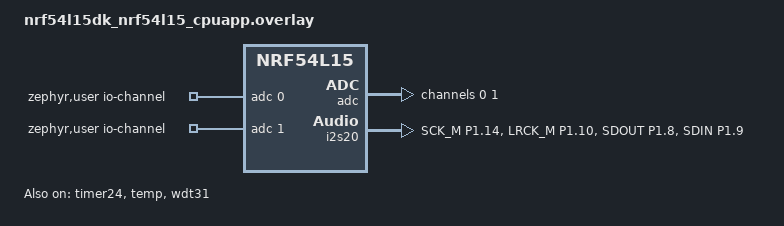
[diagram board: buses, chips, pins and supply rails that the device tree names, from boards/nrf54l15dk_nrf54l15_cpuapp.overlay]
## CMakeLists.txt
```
#
# Copyright (c) 2024 Nordic Semiconductor ASA
#
# SPDX-License-Identifier: LicenseRef-Nordic-5-Clause
#

cmake_minimum_required(VERSION 3.20.0)
find_package(Zephyr REQUIRED HINTS $ENV{ZEPHYR_BASE})
project(periph_stress)

FILE(GLOB app_sources src/*.c)

zephyr_include_directories_ifdef(CONFIG_DT_HAS_SNPS_DWC2_ENABLED ${ZEPHYR_BASE}/samples/subsys/usb/common)
zephyr_sources_ifdef(CONFIG_DT_HAS_SNPS_DWC2_ENABLED ${ZEPHYR_BASE}/samples/subsys/usb/common/sample_usbd_init.c)

target_sources(app PRIVATE ${app_sources})
```

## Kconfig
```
source "${ZEPHYR_BASE}/samples/subsys/usb/common/Kconfig.sample_usbd"

source "Kconfig.zephyr"
```

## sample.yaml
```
sample:
  name: Peripheral stress test

common:
  depends_on:
    - adc
    - gpio
    - i2c
    - pwm
    - spi
    - watchdog
  tags:
    - drivers
    - spi
    - sensors
    - ci_tests_benchmarks_peripheral_load
  harness: console

tests:
  sample.benchmarks.peripheral_stress_test.nrf54h:
    filter: not CONFIG_COVERAGE
    harness_config:
      fixture: pca63566
      type: multi_line
      ordered: false
      regex:
        - ".*Accelerometer thread has completed"
        - ".*ADC thread has completed"
        - ".*BME680 thread has completed"
        - ".*CAN thread has completed"
        - ".*Counter thread has completed"
        - ".*Flash thread has completed"
        - ".*GPIO thread has completed"
        - ".*PWM thread has completed"
        - ".*TEMP thread has completed"
        - ".*Timer thread has completed"
        - ".*WDT thread has completed"
        - ".*CPU load thread has completed"
        - ".*Clock thread has completed"
        - ".*usb_thread: Baudrate 9600"
        - ".*Bluetooth init OK"
        - ".*all \\d{1,} threads have completed"
    extra_args:
      - SHIELD=pca63566
      - SB_CONFIG_NETCORE_IPC_RADIO=y
      - SB_CONFIG_NETCORE_IPC_RADIO_BT_HCI_IPC=y
    platform_allow: nrf54h20dk/nrf54h20/cpuapp
    integration_platforms:
      - nrf54h20dk/nrf54h20/cpuapp

  sample.benchmarks.peripheral_stress_test.nrf54l:
    filter: not CONFIG_COVERAGE
    harness_config:
      fixture: pca63565
      type: multi_line
      ordered: false
      regex:
        - ".*Accelerometer thread has completed"
        - ".*ADC thread has completed"
        - ".*BME680 thread has completed"
        - ".*Counter thread has completed"
        - ".*Flash thread has completed"
        - ".*GPIO thread has completed"
        - ".*I2S thread has completed"
        - ".*PWM thread has completed"
        - ".*TEMP thread has completed"
        - ".*Timer thread has completed"
        - ".*WDT thread has completed"
        - ".*CPU load thread has completed"
        - ".*Bluetooth init OK"
        - ".*all \\d{1,} threads have completed"
    extra_args:
      - SHIELD=pca63565
    platform_allow: nrf54l15dk/nrf54l15/cpuapp
    integration_platforms:
      - nrf54l15dk/nrf54l15/cpuapp
```

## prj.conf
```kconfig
CONFIG_LOG=y

CONFIG_SENSOR=y
CONFIG_ADC=y
CONFIG_CAN=y
CONFIG_COUNTER=y
CONFIG_FLASH=y
CONFIG_GPIO=y
CONFIG_I2S=y
CONFIG_PWM=y
CONFIG_WATCHDOG=y
CONFIG_BT=y
CONFIG_BT_DEVICE_NAME="Test beacon"
CONFIG_BT_CTLR_TX_PWR_PLUS_8=y
CONFIG_ASSERT=y
```

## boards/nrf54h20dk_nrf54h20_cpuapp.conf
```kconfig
CONFIG_CLOCK_CONTROL=y

CONFIG_USB_DEVICE_STACK_NEXT=y

CONFIG_STDOUT_CONSOLE=y
CONFIG_SERIAL=y
CONFIG_UART_LINE_CTRL=y
CONFIG_USBD_CDC_ACM_CLASS=y

CONFIG_USBD_LOG_LEVEL_WRN=y
CONFIG_UDC_DRIVER_LOG_LEVEL_WRN=y
CONFIG_USBD_CDC_ACM_LOG_LEVEL_ERR=y

CONFIG_SAMPLE_USBD_PID=0x0001
CONFIG_SAMPLE_USBD_PRODUCT="USBD CDC ACM sample"

CONFIG_SOC_NRF54H20_CPURAD_ENABLE=y
```

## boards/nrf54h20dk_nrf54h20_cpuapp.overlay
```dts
/*
 * Copyright (c) 2024 Nordic Semiconductor ASA
 *
 * SPDX-License-Identifier: LicenseRef-Nordic-5-Clause
 */

/ {
	aliases {
		test-counter = &timer137;
		watchdog0 = &wdt010;
	};

	zephyr,user {
		io-channels = <&adc 0>, <&adc 1>;
	};
};

&adc {
	#address-cells = <1>;
	#size-cells = <0>;

	channel@0 {
		reg = <0>;
		zephyr,gain = "ADC_GAIN_1_2";
		zephyr,reference = "ADC_REF_INTERNAL";
		zephyr,acquisition-time = <ADC_ACQ_TIME(ADC_ACQ_TIME_MICROSECONDS, 10)>;
		zephyr,input-positive = <NRF_SAADC_AIN4>;
		zephyr,resolution = <10>;
	};

	channel@1 {
		reg = <1>;
		zephyr,gain = "ADC_GAIN_2";
		zephyr,reference = "ADC_REF_EXTERNAL0";
		zephyr,acquisition-time = <ADC_ACQ_TIME(ADC_ACQ_TIME_MICROSECONDS, 10)>;
		zephyr,input-positive = <NRF_SAADC_AIN5>;
		zephyr,resolution = <10>;
	};
};

&mx25uw63 {
	status = "okay";
};

&timer137 {
	status = "okay";
	prescaler = <4>;
};

temp_sensor: &temp_nrfs {
	status = "okay";
};

&wdt010 {
	status = "okay";
};

&zephyr_udc0 {
	cdc_acm_uart0 {
		compatible = "zephyr,cdc-acm-uart";
	};
};
```

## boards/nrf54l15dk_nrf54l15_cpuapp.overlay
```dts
/*
 * Copyright (c) 2024 Nordic Semiconductor ASA
 *
 * SPDX-License-Identifier: LicenseRef-Nordic-5-Clause
 */

/* Rev. 0.8.1:
 * P0.00 - TX_0
 * P0.01 - RX_0
 * P0.02 - RTS_0
 * P0.03 - CTS_0
 * P0.04 - Button_3
 *
 * P1.00 - 32k_XTAL1
 * P1.01 - 32k_XTAL2
 * P1.02 - NFC_1
 * P1.03 - NFC_2
 * P1.04 - TX_1
 * P1.05 - RX_1
 * P1.06 - RTS_1
 * P1.07 - CTS_1
 * P1.08 - Button_1 / I2S_SDOUT
 * P1.09 - Button_2 / I2S_SDIN
 * P1.10 - LED_1 / I2S_LRCK_M
 * P1.11 - TWIM_SCL to BME680 + ADC_ch0
 * P1.12 - TWIM_SDA to BME680 + ADC_ch1
 * P1.13 - Button_4 / CS_BME680
 * P1.14 - LED_3 / IRQ / I2S_SCK_M
 *
 * P2.00 - QSPI
 * P2.01 - QSPI
 * P2.02 - QSPI
 * P2.03 - QSPI
 * P2.04 - QSPI
 * P2.05 - QSPI
 * P2.06 - SPIM_SCK
 * P2.07 - LED_2
 * P2.08 - SPIM_MOSI to ADXL362
 * P2.09 - LED_0 / SPIM_MISO to ADXL362
 * P2.10 - CS_ADXL362
 */

/ {
	aliases {
		i2s-node0 = &i2s20;
		test-counter = &timer24;
	};

	zephyr,user {
		io-channels = <&adc 0>, <&adc 1>;
	};
};

&pinctrl {
	i2s20_default_alt: i2s20_default_alt {
		group1 {
			psels = <NRF_PSEL(I2S_SCK_M, 1, 14)>,
				<NRF_PSEL(I2S_LRCK_M, 1, 10)>,
				<NRF_PSEL(I2S_SDOUT, 1, 8)>,
				<NRF_PSEL(I2S_SDIN, 1, 9)>;
		};
	};
};

&adc {
	#address-cells = <1>;
	#size-cells = <0>;

	channel@0 {
		reg = <0>;
		zephyr,gain = "ADC_GAIN_1";
		zephyr,reference = "ADC_REF_INTERNAL";
		zephyr,acquisition-time = <ADC_ACQ_TIME(ADC_ACQ_TIME_MICROSECONDS, 10)>;
		zephyr,input-positive = <NRF_SAADC_AIN4>; /* P1.11 - I2C SCL on sensor shield */
		zephyr,resolution = <10>;
	};

	channel@1 {
		reg = <1>;
		zephyr,gain = "ADC_GAIN_1_4";
		zephyr,reference = "ADC_REF_INTERNAL";
		zephyr,acquisition-time = <ADC_ACQ_TIME_DEFAULT>;
		zephyr,input-positive = <NRF_SAADC_AIN5>; /* P1.12 - I2C SDA on sensor shield */
		zephyr,resolution = <12>;
	};
};

&i2s20 {
	status = "okay";
	pinctrl-0 = <&i2s20_default_alt>;
	pinctrl-names = "default";
};

&timer24 {
	status = "okay";
	prescaler = <4>;
};

temp_sensor: &temp {
	status = "okay";
};

&wdt31 {
	status = "okay";
};
```

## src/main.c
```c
/*
 * Copyright (c) 2024 Nordic Semiconductor ASA
 *
 * SPDX-License-Identifier: LicenseRef-Nordic-5-Clause
 */

#include <zephyr/logging/log.h>
LOG_MODULE_REGISTER(main, LOG_LEVEL_INF);

#include <zephyr/kernel.h>
#include <zephyr/device.h>
#include "common.h"

/* Thread status */
atomic_t started_threads;
atomic_t completed_threads;

/* Watchdog status: */
extern volatile uint32_t wdt_status;

/* Main thread */
int main(void)
{
	/* Check status of flag that is set when watchdog fires */
	if (wdt_status == WDT_TAG) {
		LOG_INF("Starting after Watchdog has expired");
	} else {
		LOG_INF("That wasn't Watchdog");
	}
	wdt_status = 0U;

	/* Wait for threads to complete */
	while (atomic_get(&started_threads) < 1) {
		LOG_DBG("%ld threads were started", atomic_get(&started_threads));
		k_msleep(500);
	}
	while (atomic_get(&completed_threads) < atomic_get(&started_threads)) {
		LOG_DBG("%ld threads were started, %ld has completed",
			atomic_get(&started_threads), atomic_get(&completed_threads));
		k_msleep(500);
	}
	LOG_INF("main: all %ld threads have completed", atomic_get(&completed_threads));
}
```

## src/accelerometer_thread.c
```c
/*
 * Copyright (c) 2024 Nordic Semiconductor ASA
 *
 * SPDX-License-Identifier: LicenseRef-Nordic-5-Clause
 */

#include <zephyr/logging/log.h>
LOG_MODULE_REGISTER(accel, LOG_LEVEL_INF);

#include <zephyr/drivers/sensor.h>
#include "common.h"

static const struct device *const accelerometer = DEVICE_DT_GET(DT_ALIAS(accel0));

/* Accelerometer thread */
static void accel_thread(void *arg1, void *arg2, void *arg3)
{
	ARG_UNUSED(arg1);
	ARG_UNUSED(arg2);
	ARG_UNUSED(arg3);

	int ret;
	struct sensor_value samples[3];
	double latest[3];
	double average[3] = {0.0};

	atomic_inc(&started_threads);

	if (!device_is_ready(accelerometer)) {
		LOG_ERR("Device %s is not ready.", accelerometer->name);
		atomic_inc(&completed_threads);
		return;
	}

	for (int i = 0; i < (ACCEL_THREAD_COUNT_MAX * ACCEL_THREAD_OVERSAMPLING); i++) {
		/* Capture acceleration value */
		ret = sensor_sample_fetch(accelerometer);
		if (ret < 0) {
			LOG_ERR("%s: sensor_sample_fetch() returned: %d", accelerometer->name, ret);
			atomic_inc(&completed_threads);
			return;
		}

		/* Retrieve samples */
		ret = sensor_channel_get(accelerometer, SENSOR_CHAN_ACCEL_XYZ, samples);
		if (ret < 0) {
			LOG_ERR("%s: sensor_channel_get() returned: %d", accelerometer->name, ret);
			atomic_inc(&completed_threads);
			return;
		}

		/* Calculate average */
		for (int axis = 0; axis < 3; axis++) {
			latest[axis] = sensor_value_to_double(&samples[axis]);
			average[axis] = (average[axis] + latest[axis]) / 2;
		}

		/* Print result */
		if ((i % ACCEL_THREAD_OVERSAMPLING) == 0) {
			LOG_INF("%10s - X: %6.2f; Y: %6.2f; Z: %6.2f",
				accelerometer->name, average[0], average[1], average[2]);
		}

		k_msleep(ACCEL_THREAD_SLEEP / ACCEL_THREAD_OVERSAMPLING);
	}
	LOG_INF("Accelerometer thread has completed");

	atomic_inc(&completed_threads);
}

K_THREAD_DEFINE(thread_accel_id, ACCEL_THREAD_STACKSIZE, accel_thread, NULL, NULL, NULL,
	K_PRIO_PREEMPT(ACCEL_THREAD_PRIORITY), 0, 0);
```

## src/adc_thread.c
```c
/*
 * Copyright (c) 2024 Nordic Semiconductor ASA
 *
 * SPDX-License-Identifier: LicenseRef-Nordic-5-Clause
 */

#include <zephyr/logging/log.h>
LOG_MODULE_REGISTER(adc, LOG_LEVEL_INF);

#include <zephyr/drivers/adc.h>
#include "common.h"

#if !DT_NODE_EXISTS(DT_PATH(zephyr_user)) || \
	!DT_NODE_HAS_PROP(DT_PATH(zephyr_user), io_channels)
#error "No suitable devicetree overlay specified"
#endif

#define DT_SPEC_AND_COMMA(node_id, prop, idx)	ADC_DT_SPEC_GET_BY_IDX(node_id, idx),

/* Data of ADC io-channels specified in devicetree. */
static const struct adc_dt_spec adc_channels[] = {
	DT_FOREACH_PROP_ELEM(DT_PATH(zephyr_user), io_channels, DT_SPEC_AND_COMMA)
};

/* Get the number of channels defined on the DTS. */
#define CHANNEL_COUNT ARRAY_SIZE(adc_channels)

/* ADC thread */
static void adc_thread(void *arg1, void *arg2, void *arg3)
{
	ARG_UNUSED(arg1);
	ARG_UNUSED(arg2);
	ARG_UNUSED(arg3);

	int ret;
	uint16_t buf;
	struct adc_sequence sequence = {
		.buffer = &buf,
		/* buffer size in bytes, not number of samples */
		.buffer_size = sizeof(buf),
	};
	uint16_t average[CHANNEL_COUNT] = { 0 };
	int32_t average_mv[CHANNEL_COUNT];

	atomic_inc(&started_threads);

	/* Configure channels individually prior to sampling. */
	for (size_t i = 0U; i < CHANNEL_COUNT; i++) {
		if (!adc_is_ready_dt(&adc_channels[i])) {
			LOG_ERR("ADC controller devivce %s is not ready",
				adc_channels[i].dev->name);
			atomic_inc(&completed_threads);
			return;
		}

		ret = adc_channel_setup_dt(&adc_channels[i]);
		if (ret < 0) {
			LOG_ERR("Could not setup channel #%d (%d)", i, ret);
			atomic_inc(&completed_threads);
			return;
		}
	}

	for (int i = 0; i < (ADC_THREAD_COUNT_MAX * ADC_THREAD_OVERSAMPLING); i++) {
		/* For each ADC channel */
		for (size_t i = 0U; i < CHANNEL_COUNT; i++) {

			/* Read ADC channel */
			ret = adc_sequence_init_dt(&adc_channels[i], &sequence);
			if (ret < 0) {
				LOG_ERR("adc_sequence_init_dt(%d) failed (%d)", i, ret);
				atomic_inc(&completed_threads);
				return;
			}

			ret = adc_read_dt(&adc_channels[i], &sequence);
			if (ret < 0) {
				LOG_ERR("adc_read_dt(%d) failed (%d)", i, ret);
				atomic_inc(&completed_threads);
				return;
			}

			/* Calculate running average */
			average[i] = (average[i] + buf) >> 1;
			average_mv[i] = average[i];

			ret = adc_raw_to_millivolts_dt(&adc_channels[i], &average_mv[i]);
			if (ret < 0) {
				LOG_ERR("adc_raw_to_millivolts_dt(%d) failed (%d)", i, ret);
				atomic_inc(&completed_threads);
				return;
			}
		}

		/* Print result */
		if ((i % ADC_THREAD_OVERSAMPLING) == 0) {
			LOG_INF("CH0 = %d (%d mv), CH1 = %d (%d mv)",
				average[0], average_mv[0], average[1], average_mv[1]);
		}

		k_msleep(ADC_THREAD_SLEEP / ADC_THREAD_OVERSAMPLING);
	}
	LOG_INF("ADC thread has completed");

	atomic_inc(&completed_threads);
}

K_THREAD_DEFINE(thread_adc_id, ADC_THREAD_STACKSIZE, adc_thread, NULL, NULL, NULL,
	K_PRIO_PREEMPT(ADC_THREAD_PRIORITY), 0, 0);
```

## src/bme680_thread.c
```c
/*
 * Copyright (c) 2024 Nordic Semiconductor ASA
 *
 * SPDX-License-Identifier: LicenseRef-Nordic-5-Clause
 */

#include <zephyr/logging/log.h>
LOG_MODULE_REGISTER(be680, LOG_LEVEL_INF);

#include <zephyr/drivers/sensor.h>
#include "common.h"

static const struct device *const bme680 = DEVICE_DT_GET_ONE(bosch_bme680);

/* BME680 thread */
static void bme680_thread(void *arg1, void *arg2, void *arg3)
{
	ARG_UNUSED(arg1);
	ARG_UNUSED(arg2);
	ARG_UNUSED(arg3);

	int ret;
	struct sensor_value samples[4]; /* 0-temp, 1-press, 2-humidity, 3-gas_res*/
	int32_t latest_val1[4];
	int32_t latest_val2[4];
	int32_t average_val1[4] = {0};
	int32_t average_val2[4] = {0};

	atomic_inc(&started_threads);

	if (!device_is_ready(bme680)) {
		LOG_ERR("Device %s is not ready.", bme680->name);
		atomic_inc(&completed_threads);
		return;
	}

	for (int i = 0; i < (BME680_THREAD_COUNT_MAX * BME680_THREAD_OVERSAMPLING); i++) {
		/* Capture samples */
		ret = sensor_sample_fetch(bme680);
		if (ret < 0) {
			LOG_ERR("%s: sensor_sample_fetch() returned: %d", bme680->name, ret);
			atomic_inc(&completed_threads);
			return;
		}

		/* Retrieve samples */
		sensor_channel_get(bme680, SENSOR_CHAN_AMBIENT_TEMP, &samples[0]);
		if (ret < 0) {
			LOG_ERR("%s: sensor_channel_get(TEMP) returned: %d", bme680->name, ret);
			atomic_inc(&completed_threads);
			return;
		}
		sensor_channel_get(bme680, SENSOR_CHAN_PRESS, &samples[1]);
		if (ret < 0) {
			LOG_ERR("%s: sensor_channel_get(PRESS) returned: %d", bme680->name, ret);
			atomic_inc(&completed_threads);
			return;
		}
		sensor_channel_get(bme680, SENSOR_CHAN_HUMIDITY, &samples[2]);
		if (ret < 0) {
			LOG_ERR("%s: sensor_channel_get(HUMIDITY) returned: %d", bme680->name, ret);
			atomic_inc(&completed_threads);
			return;
		}
		sensor_channel_get(bme680, SENSOR_CHAN_GAS_RES, &samples[3]);
		if (ret < 0) {
			LOG_ERR("%s: sensor_channel_get(GAS_RES) returned: %d", bme680->name, ret);
			atomic_inc(&completed_threads);
			return;
		}

		/* Calculate average */
		for (int property = 0; property < 4; property++) {
			latest_val1[property] = samples[property].val1;
			latest_val2[property] = samples[property].val2;
			average_val1[property] =
				(average_val1[property] + latest_val1[property]) / 2;
			average_val2[property] =
				(average_val2[property] + latest_val2[property]) / 2;
		}

		if ((i % BME680_THREAD_OVERSAMPLING) == 0) {
			/* Print result */
			LOG_INF("%10s - T: %d.%06d; P: %d.%06d; H: %d.%06d; G: %d.%06d",
				bme680->name,
				average_val1[0], average_val2[0], average_val1[1], average_val2[1],
				average_val1[2], average_val2[2], average_val1[3], average_val2[3]);
		}

		k_msleep(BME680_THREAD_SLEEP / BME680_THREAD_OVERSAMPLING);
	}
	LOG_INF("BME680 thread has completed");

	atomic_inc(&completed_threads);
}

K_THREAD_DEFINE(thread_bme680_id, BME680_THREAD_STACKSIZE, bme680_thread, NULL, NULL, NULL,
	K_PRIO_PREEMPT(BME680_THREAD_PRIORITY), 0, 0);
```

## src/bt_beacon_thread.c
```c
/*
 * Copyright (c) 2025 Nordic Semiconductor ASA
 *
 * SPDX-License-Identifier: LicenseRef-Nordic-5-Clause
 */

#include <zephyr/types.h>
#include <stddef.h>
#include <zephyr/sys/printk.h>
#include <zephyr/sys/util.h>
#include <zephyr/logging/log.h>
#include <zephyr/bluetooth/bluetooth.h>
#include <zephyr/bluetooth/hci.h>
#include "common.h"

LOG_MODULE_REGISTER(bt_thread, LOG_LEVEL_INF);

#define DEVICE_NAME CONFIG_BT_DEVICE_NAME
#define DEVICE_NAME_LEN (sizeof(DEVICE_NAME) - 1)

/*
 * Set Advertisement data. Based on the Eddystone specification:
 * https://github.com/google/eddystone/blob/master/protocol-specification.md
 * https://github.com/google/eddystone/tree/master/eddystone-url
 */
static const struct bt_data ad[] = {
	BT_DATA_BYTES(BT_DATA_FLAGS, BT_LE_AD_NO_BREDR),
	BT_DATA_BYTES(BT_DATA_UUID16_ALL, 0xaa, 0xfe),
	BT_DATA_BYTES(BT_DATA_SVC_DATA16,
		      0xaa, 0xfe, /* Eddystone UUID */
		      0x10, /* Eddystone-URL frame type */
		      0x00, /* Calibrated Tx power at 0m */
		      0x00, /* URL Scheme Prefix http://www. */
		      'z', 'e', 'p', 'h', 'y', 'r',
		      'p', 'r', 'o', 'j', 'e', 'c', 't',
		      0x08) /* .org */
};

/* Set Scan Response data */
static const struct bt_data sd[] = {
	BT_DATA(BT_DATA_NAME_COMPLETE, DEVICE_NAME, DEVICE_NAME_LEN),
};

static void bt_ready(int err)
{
	char addr_s[BT_ADDR_LE_STR_LEN];
	bt_addr_le_t addr = {0};
	size_t count = 1;

	if (err) {
		LOG_ERR("Bluetooth init failed (err %d)", err);
		return;
	}

	LOG_INF("Bluetooth initialized\n");

	/* Start advertising */
	err = bt_le_adv_start(BT_LE_ADV_NCONN_IDENTITY, ad, ARRAY_SIZE(ad),
			      sd, ARRAY_SIZE(sd));
	if (err) {
		LOG_ERR("Advertising failed to start (err %d)", err);
		return;
	}


	/* For connectable advertising you would use
	 * bt_le_oob_get_local().  For non-connectable non-identity
	 * advertising an non-resolvable private address is used;
	 * there is no API to retrieve that.
	 */

	bt_id_get(&addr, &count);
	bt_addr_le_to_str(&addr, addr_s, sizeof(addr_s));

	LOG_INF("Beacon started, advertising as %s", addr_s);
}

/* BT thread */
static void bt_thread(void *arg1, void *arg2, void *arg3)
{
	ARG_UNUSED(arg1);
	ARG_UNUSED(arg2);
	ARG_UNUSED(arg3);

	LOG_INF("Starting BT beacon");

	/* Initialize the Bluetooth Subsystem */
	if (bt_enable(bt_ready)) {
		LOG_ERR("Bluetooth init failed");
	} else {
		LOG_INF("Bluetooth init OK");
	}
}

K_THREAD_DEFINE(thread_bt_id, BT_THREAD_STACKSIZE, bt_thread, NULL, NULL, NULL,
	K_PRIO_PREEMPT(BT_THREAD_PRIORITY), 0, 0);
```

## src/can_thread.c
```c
/*
 * Copyright (c) 2024 Nordic Semiconductor ASA
 *
 * SPDX-License-Identifier: LicenseRef-Nordic-5-Clause
 */

#include <zephyr/logging/log.h>
LOG_MODULE_REGISTER(can, LOG_LEVEL_INF);

#include <zephyr/drivers/can.h>
#include "common.h"

#if DT_NODE_HAS_STATUS(DT_CHOSEN(zephyr_canbus), okay)

static const struct device *const can_dev = DEVICE_DT_GET(DT_CHOSEN(zephyr_canbus));
static int rx_counter;

const struct can_frame test_std_frame = {
	.flags   = 0,
	.id      = 0x555,
	.dlc     = 8,
	.data    = {1, 2, 3, 4, 5, 6, 7, 8}
};

const struct can_filter test_std_filter = {
	.flags = 0U,
	.id = 0x555,
	.mask = CAN_STD_ID_MASK
};

void tx_callback(const struct device *dev, int error, void *user_data)
{
	char *sender = (char *)user_data;

	if (error != 0) {
		LOG_ERR("Sending failed [%d]\nSender: %s", error, sender);
	}
}

void rx_callback(const struct device *dev, struct can_frame *frame, void *user_data)
{
	rx_counter++;
	LOG_INF("Received CAN frame (# %d)", rx_counter);
}

/* CAN thread */
static void can_thread(void *arg1, void *arg2, void *arg3)
{
	ARG_UNUSED(arg1);
	ARG_UNUSED(arg2);
	ARG_UNUSED(arg3);

	int ret;

	atomic_inc(&started_threads);

	if (!device_is_ready(can_dev)) {
		LOG_ERR("Device %s is not ready.", can_dev->name);
		atomic_inc(&completed_threads);
		return;
	}

	/* failsafe */
	(void)can_stop(can_dev);

	/* set loopback mode */
	ret = can_set_mode(can_dev, CAN_MODE_LOOPBACK);
	if (ret < 0) {
		LOG_ERR("can_set_mode() returned %d", ret);
		atomic_inc(&completed_threads);
		return;
	}

	ret = can_start(can_dev);
	if (ret < 0) {
		LOG_ERR("can_start() returned %d", ret);
		atomic_inc(&completed_threads);
		return;
	}

	/* Configure CAN RX filter */
	ret = can_add_rx_filter(can_dev, rx_callback, NULL, &test_std_filter);
	if (ret < 0) {
		LOG_ERR("can_add_rx_filter() returned %d", ret);
		atomic_inc(&completed_threads);
		return;
	}

	while (rx_counter < CAN_THREAD_COUNT_MAX) {
		/* Send CAN message */
		ret = can_send(can_dev, &test_std_frame, K_FOREVER, tx_callback, "CAN thread");
		if (ret < 0) {
			LOG_ERR("can_send() returned: %d", ret);
			atomic_inc(&completed_threads);
			return;
		}

		k_msleep(CAN_THREAD_SLEEP);
	}

	ret = can_stop(can_dev);
	if (ret < 0) {
		LOG_ERR("can_stop() returned %d", ret);
		atomic_inc(&completed_threads);
		return;
	}

	LOG_INF("CAN thread has completed");

	atomic_inc(&completed_threads);
}

K_THREAD_DEFINE(thread_can_id, CAN_THREAD_STACKSIZE, can_thread, NULL, NULL, NULL,
	K_PRIO_PREEMPT(CAN_THREAD_PRIORITY), 0, 0);

#else
#pragma message("CAN thread skipped due to missing node in the DTS")
#endif
```

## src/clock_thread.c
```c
/*
 * Copyright (c) 2024 Nordic Semiconductor ASA
 *
 * SPDX-License-Identifier: LicenseRef-Nordic-5-Clause
 */
#ifdef CONFIG_CLOCK_CONTROL_NRF2
#include "common.h"

#include <zephyr/logging/log.h>
LOG_MODULE_REGISTER(clock, LOG_LEVEL_INF);

#include <zephyr/devicetree.h>
#include <zephyr/devicetree/clocks.h>
#include <zephyr/drivers/clock_control/nrf_clock_control.h>
#include <zephyr/kernel.h>

struct test_clk_context {
	const struct device *clk_dev;
	const struct nrf_clock_spec *clk_specs;
	size_t clk_specs_size;
};

const struct nrf_clock_spec test_clk_specs_hsfll[] = {
	{
		.frequency = MHZ(128),
		.accuracy = 0,
		.precision = NRF_CLOCK_CONTROL_PRECISION_DEFAULT,
	},
	{
		.frequency = MHZ(320),
		.accuracy = 0,
		.precision = NRF_CLOCK_CONTROL_PRECISION_DEFAULT,
	},
	{
		.frequency = MHZ(64),
		.accuracy = 0,
		.precision = NRF_CLOCK_CONTROL_PRECISION_DEFAULT,
	},
};

const struct nrf_clock_spec test_clk_specs_fll16m[] = {
	{
		.frequency = MHZ(16),
		.accuracy = 20000,
		.precision = NRF_CLOCK_CONTROL_PRECISION_DEFAULT,
	},
	{
		.frequency = MHZ(16),
		.accuracy = 5020,
		.precision = NRF_CLOCK_CONTROL_PRECISION_DEFAULT,
	},
	{
		.frequency = MHZ(16),
		.accuracy = 30,
		.precision = NRF_CLOCK_CONTROL_PRECISION_DEFAULT,
	},
};

static const struct test_clk_context fll16m_test_clk_contexts[] = {
	{
		.clk_dev = DEVICE_DT_GET(DT_NODELABEL(fll16m)),
		.clk_specs = test_clk_specs_fll16m,
		.clk_specs_size = ARRAY_SIZE(test_clk_specs_fll16m),
	},
};

static const struct test_clk_context cpuapp_hsfll_test_clk_contexts[] = {
	{
		.clk_dev = DEVICE_DT_GET(DT_NODELABEL(cpuapp_hsfll)),
		.clk_specs = test_clk_specs_hsfll,
		.clk_specs_size = ARRAY_SIZE(test_clk_specs_hsfll),
	},
};

const struct nrf_clock_spec test_clk_specs_lfclk[] = {
	{
		.frequency = 32768,
		.accuracy = 0,
		.precision = NRF_CLOCK_CONTROL_PRECISION_DEFAULT,
	},
	{
		.frequency = 32768,
		.accuracy = 20,
		.precision = NRF_CLOCK_CONTROL_PRECISION_DEFAULT,
	},
	{
		.frequency = 32768,
		.accuracy = 20,
		.precision = NRF_CLOCK_CONTROL_PRECISION_HIGH,
	},
};

static const struct test_clk_context lfclk_test_clk_contexts[] = {
	{
		.clk_dev = DEVICE_DT_GET(DT_NODELABEL(lfclk)),
		.clk_specs = test_clk_specs_lfclk,
		.clk_specs_size = ARRAY_SIZE(test_clk_specs_lfclk),
	},
};

static void test_request_release_clock_spec(const struct device *clk_dev,
					    const struct nrf_clock_spec *clk_spec)
{
	int ret = 0;
	int res = 0;
	struct onoff_client cli;
	uint32_t rate;
	bool rate_supported = true;

	LOG_INF("Clock under test: %s", clk_dev->name);
	sys_notify_init_spinwait(&cli.notify);
	ret = nrf_clock_control_request(clk_dev, clk_spec, &cli);
	LOG_INF("Clock control request return value: %d", ret);
	if (ret != 0) {
		LOG_ERR("Clock control request failed");
		atomic_inc(&completed_threads);
		return;
	}
	do {
		ret = sys_notify_fetch_result(&cli.notify, &res);
		k_yield();
	} while (ret == -EAGAIN);
	LOG_INF("Clock control request response code: %d", res);
	if (res != 0) {
		LOG_ERR("Wrong clock control request response code");
		atomic_inc(&completed_threads);
		return;
	}
	ret = clock_control_get_rate(clk_dev, NULL, &rate);
	LOG_INF("Clock control get rate response code: %d", ret);
	if (ret == -ENOSYS) {
		LOG_INF("Clock control get rate not supported");
		rate_supported = false;
	} else if (ret != 0) {
		LOG_ERR("Clock control get rate failed");
		atomic_inc(&completed_threads);
		return;
	}
	if (rate_supported && rate != clk_spec->frequency) {
		LOG_ERR("Invalid rate: %d", rate);
		atomic_inc(&completed_threads);
		return;
	}
	k_msleep(1000);
	ret = nrf_clock_control_release(clk_dev, clk_spec);
	if (ret != ONOFF_STATE_ON) {
		LOG_ERR("Clock control release failed");
		atomic_inc(&completed_threads);
		return;
	}
}

static void test_clock_control_request(const struct test_clk_context *clk_contexts,
				       size_t contexts_size)
{
	const struct test_clk_context *clk_context;
	size_t clk_specs_size;
	const struct device *clk_dev;
	const struct nrf_clock_spec *clk_spec;

	for (size_t i = 0; i < contexts_size; i++) {
		clk_context = &clk_contexts[i];
		clk_specs_size = clk_context->clk_specs_size;

		for (size_t u = 0; u < clk_specs_size; u++) {
			clk_dev = clk_context->clk_dev;
			clk_spec = &clk_context->clk_specs[u];

			LOG_INF("Applying clock (%s) spec: frequency %d, accuracy %d, precision "
				"%d",
				clk_dev->name, clk_spec->frequency, clk_spec->accuracy,
				clk_spec->precision);
			test_request_release_clock_spec(clk_dev, clk_spec);
		}
	}
}

/* Clock thread */
static void clock_thread(void *arg1, void *arg2, void *arg3)
{
	ARG_UNUSED(arg1);
	ARG_UNUSED(arg2);
	ARG_UNUSED(arg3);

	atomic_inc(&started_threads);

	k_msleep(100);
	test_clock_control_request(cpuapp_hsfll_test_clk_contexts,
				   ARRAY_SIZE(cpuapp_hsfll_test_clk_contexts));

	test_clock_control_request(fll16m_test_clk_contexts, ARRAY_SIZE(fll16m_test_clk_contexts));

	test_clock_control_request(lfclk_test_clk_contexts, ARRAY_SIZE(lfclk_test_clk_contexts));

	LOG_INF("Clock thread has completed");

	atomic_inc(&completed_threads);
}

K_THREAD_DEFINE(thread_clock_id, CLOCK_THREAD_STACKSIZE, clock_thread, NULL, NULL, NULL,
		K_PRIO_PREEMPT(CLOCK_THREAD_PRIORITY), 0, 0);
#endif
```

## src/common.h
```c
/*
 * Copyright (c) 2024 Nordic Semiconductor ASA
 *
 * SPDX-License-Identifier: LicenseRef-Nordic-5-Clause
 */

#ifndef PERIPHERAL_STRESS_TEST_H
#define PERIPHERAL_STRESS_TEST_H

#include <zephyr/kernel.h>
#include <zephyr/device.h>

/* Thread status */
extern atomic_t started_threads;
extern atomic_t completed_threads;

/* Accelerator readout via SPI: */
#define ACCEL_THREAD_COUNT_MAX		(40)
#define ACCEL_THREAD_OVERSAMPLING	(3)
#define ACCEL_THREAD_STACKSIZE		(1024)
#define ACCEL_THREAD_PRIORITY		(5)
#define ACCEL_THREAD_SLEEP			(200)

/* ADC thread: */
#define ADC_THREAD_COUNT_MAX	(40)
#define ADC_THREAD_OVERSAMPLING (3)
#define ADC_THREAD_STACKSIZE	(1024)
#define ADC_THREAD_PRIORITY		(5)
#define ADC_THREAD_SLEEP		(200)

/* BME680 environment sensor readout via I2C: */
#define BME680_THREAD_COUNT_MAX		(40)
#define BME680_THREAD_OVERSAMPLING	(2)
#define BME680_THREAD_STACKSIZE		(1024)
#define BME680_THREAD_PRIORITY		(5)
#define BME680_THREAD_SLEEP			(200)

/* CAN thread: */
#define CAN_THREAD_COUNT_MAX	(40)
#define CAN_THREAD_STACKSIZE	(1024)
#define CAN_THREAD_PRIORITY		(5)
#define CAN_THREAD_SLEEP		(200)

/* Counter thread: */
#define COUNTER_THREAD_COUNT_MAX	(40)
#define COUNTER_THREAD_STACKSIZE	(512)
#define COUNTER_THREAD_PRIORITY		(5)
#define COUNTER_THREAD_PERIOD		(200)

/* FLASH thread: */
#define FLASH_THREAD_COUNT_MAX	(40)
#define FLASH_THREAD_STACKSIZE	(2048)
#define FLASH_THREAD_PRIORITY	(5)
#define FLASH_THREAD_SLEEP		(200)

/* GPIO thread: */
#define GPIO_THREAD_COUNT_MAX	(40)
#define GPIO_THREAD_STACKSIZE	(512)
#define GPIO_THREAD_PRIORITY	(5)
#define GPIO_THREAD_SLEEP		(200)

/* I2S thread: */
#define I2S_THREAD_COUNT_MAX	(40)
#define I2S_THREAD_STACKSIZE	(1024)
#define I2S_THREAD_PRIORITY		(5)
#define I2S_THREAD_SLEEP		(200)

/* PWM thread: */
#define PWM_THREAD_COUNT_MAX	(40)
#define PWM_THREAD_OVERSAMPLING	(10)
#define PWM_THREAD_STACKSIZE	(512)
#define PWM_THREAD_PRIORITY		(5)
#define PWM_THREAD_SLEEP		(200)

/* TEMP thread: */
#define TEMP_THREAD_COUNT_MAX	(40)
#define TEMP_THREAD_STACKSIZE	(512)
#define TEMP_THREAD_PRIORITY	(5)
#define TEMP_THREAD_PERIOD		(200)

/* Timer thread: */
#define TIMER_THREAD_COUNT_MAX	(40)
#define TIMER_THREAD_STACKSIZE	(512)
#define TIMER_THREAD_PRIORITY	(5)
#define TIMER_THREAD_PERIOD		(200)

/* Watchdog thread: */
#define WDT_THREAD_COUNT_MAX	(40)
#define WDT_THREAD_STACKSIZE	(512)
#define WDT_THREAD_PRIORITY		(4)
#define WDT_THREAD_PERIOD		(200)
#define WDT_WINDOW_MAX			(2 * WDT_THREAD_PERIOD)
#define WDT_TAG					(0x12345678U)

/* Clock thread: */
#define CLOCK_THREAD_STACKSIZE	(512)
#define CLOCK_THREAD_PRIORITY	(4)

/* Busy load thread: */
#define LOAD_THREAD_STACKSIZE	(1024)
#define LOAD_THREAD_PRIORITY	(CONFIG_NUM_PREEMPT_PRIORITIES - 1)
#define LOAD_THREAD_DURATION	(ACCEL_THREAD_SLEEP * (ACCEL_THREAD_COUNT_MAX + 2))

/* USB thread */
#define USB_THREAD_COUNT_MAX	(40)
#define USB_THREAD_STACKSIZE	(1024)
#define USB_THREAD_PRIORITY	    (5)
#define USB_THREAD_SLEEP		(200)

/* BT thread */
#define BT_THREAD_COUNT_MAX	(40)
#define BT_THREAD_STACKSIZE	(1024)
#define BT_THREAD_PRIORITY	(5)
#define BT_THREAD_SLEEP		(200)

#endif
```

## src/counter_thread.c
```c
/*
 * Copyright (c) 2024 Nordic Semiconductor ASA
 *
 * SPDX-License-Identifier: LicenseRef-Nordic-5-Clause
 */

#include <zephyr/logging/log.h>
LOG_MODULE_REGISTER(cnt, LOG_LEVEL_INF);

#include <zephyr/drivers/counter.h>
#include "common.h"

#define ALARM_CHANNEL_ID	(0)

static const struct device *const counter_dev = DEVICE_DT_GET(DT_ALIAS(test_counter));
static struct counter_alarm_cfg alarm_cfg;
static int counter_expire_count;


static void my_counter_cb(const struct device *counter_dev,
	uint8_t chan_id, uint32_t ticks, void *user_data)
{
	int ret;
	uint32_t now_ticks;
	uint64_t now_usec;
	uint64_t expire_usec;

	counter_expire_count++;

	/* Get current ticks */
	ret = counter_get_value(counter_dev, &now_ticks);
	if (ret) {
		LOG_ERR("counter_get_value() failed (%d)", ret);
		return;
	}

	/* Set a new alarm */
	if (counter_expire_count < COUNTER_THREAD_COUNT_MAX) {
		ret = counter_set_channel_alarm(counter_dev, ALARM_CHANNEL_ID, user_data);
		if (ret != 0) {
			LOG_ERR("counter_set_channel_alarm() failed (%d)", ret);
		}
	} else {
		counter_stop(counter_dev);
	}

	/* Convert ticks to us */
	expire_usec = counter_ticks_to_us(counter_dev, ticks);
	now_usec = counter_ticks_to_us(counter_dev, now_ticks);

	LOG_INF("Counter expired %d times (at %lld us), restarted just after %lld us",
		counter_expire_count, expire_usec, now_usec);
}

/* Counter thread */
static void counter_thread(void *arg1, void *arg2, void *arg3)
{
	ARG_UNUSED(arg1);
	ARG_UNUSED(arg2);
	ARG_UNUSED(arg3);

	int ret;

	atomic_inc(&started_threads);

	if (!device_is_ready(counter_dev)) {
		LOG_ERR("Device %s is not ready.", counter_dev->name);
		atomic_inc(&completed_threads);
		return;
	}

	counter_start(counter_dev);

	alarm_cfg.flags = 0;
	alarm_cfg.ticks = counter_us_to_ticks(counter_dev, COUNTER_THREAD_PERIOD * 1000);
	alarm_cfg.callback = my_counter_cb;
	alarm_cfg.user_data = &alarm_cfg;

	ret = counter_set_channel_alarm(counter_dev, ALARM_CHANNEL_ID, &alarm_cfg);
	if (-EINVAL == ret) {
		LOG_ERR("Alarm settings invalid");
		atomic_inc(&completed_threads);
		return;
	} else if (-ENOTSUP == ret) {
		LOG_ERR("Alarm setting request not supported");
		atomic_inc(&completed_threads);
		return;
	} else if (ret != 0) {
		LOG_ERR("counter_set_channel_alarm() failed (%d)", ret);
		atomic_inc(&completed_threads);
		return;
	}

	while (counter_expire_count < COUNTER_THREAD_COUNT_MAX) {
		/* Wait for condition to be meet */
		k_msleep(100);
	}

	LOG_INF("Counter thread has completed");

	atomic_inc(&completed_threads);
}

K_THREAD_DEFINE(thread_counter_id, COUNTER_THREAD_STACKSIZE, counter_thread, NULL, NULL, NULL,
	K_PRIO_PREEMPT(COUNTER_THREAD_PRIORITY), 0, 0);
```

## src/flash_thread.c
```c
/*
 * Copyright (c) 2024 Nordic Semiconductor ASA
 *
 * SPDX-License-Identifier: LicenseRef-Nordic-5-Clause
 */

#include <zephyr/logging/log.h>
LOG_MODULE_REGISTER(flash_thd, LOG_LEVEL_INF);

#include <zephyr/drivers/flash.h>
#include <zephyr/devicetree.h>
#include "common.h"

#if DT_HAS_COMPAT_STATUS_OKAY(jedec_spi_nor)
#define FLASH_NODE DT_COMPAT_GET_ANY_STATUS_OKAY(jedec_spi_nor)
#elif DT_HAS_COMPAT_STATUS_OKAY(jedec_mspi_nor)
#define FLASH_NODE DT_COMPAT_GET_ANY_STATUS_OKAY(jedec_mspi_nor)
#elif DT_HAS_COMPAT_STATUS_OKAY(nordic_qspi_nor)
#define FLASH_NODE DT_COMPAT_GET_ANY_STATUS_OKAY(nordic_qspi_nor)
#else
#error Unsupported flash driver
#define FLASH_NODE DT_INVALID_NODE
#endif

#define TEST_AREA_OFFSET	(0xff000)
#define EXPECTED_SIZE		(512)

static const struct device *const flash_dev = DEVICE_DT_GET(FLASH_NODE);

/* Flash thread */
static void flash_thread(void *arg1, void *arg2, void *arg3)
{
	ARG_UNUSED(arg1);
	ARG_UNUSED(arg2);
	ARG_UNUSED(arg3);

	int ret;
	uint8_t buf[EXPECTED_SIZE];

	atomic_inc(&started_threads);

	if (!device_is_ready(flash_dev)) {
		LOG_ERR("Device %s is not ready.", flash_dev->name);
		atomic_inc(&completed_threads);
		return;
	}

	for (int i = 0; i < FLASH_THREAD_COUNT_MAX; i++) {
		/* Read external memory */
		ret = flash_read(flash_dev, TEST_AREA_OFFSET, buf, EXPECTED_SIZE);
		if (ret < 0) {
			LOG_ERR("flash_read() failed (%d)", ret);
			atomic_inc(&completed_threads);
			return;
		}
		LOG_INF("flash_read() #%d done", i);

		k_msleep(FLASH_THREAD_SLEEP);
	}
	LOG_INF("Flash thread has completed");

	atomic_inc(&completed_threads);
}

K_THREAD_DEFINE(thread_flash_id, FLASH_THREAD_STACKSIZE, flash_thread, NULL, NULL, NULL,
	K_PRIO_PREEMPT(FLASH_THREAD_PRIORITY), 0, 0);
```

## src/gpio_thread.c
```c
/*
 * Copyright (c) 2024 Nordic Semiconductor ASA
 *
 * SPDX-License-Identifier: LicenseRef-Nordic-5-Clause
 */

#include <zephyr/logging/log.h>
LOG_MODULE_REGISTER(gpio, LOG_LEVEL_INF);

#include <zephyr/drivers/gpio.h>
#include "common.h"

#define GPIO_NODE		DT_ALIAS(led2)
#if !DT_NODE_HAS_STATUS(GPIO_NODE, okay)
#error "Unsupported board: led2 devicetree alias is not defined"
#endif

static const struct gpio_dt_spec gpio_spec = GPIO_DT_SPEC_GET(GPIO_NODE, gpios);

/* GPIO thread */
static void gpio_thread(void *arg1, void *arg2, void *arg3)
{
	ARG_UNUSED(arg1);
	ARG_UNUSED(arg2);
	ARG_UNUSED(arg3);

	int ret;

	atomic_inc(&started_threads);

	if (!gpio_is_ready_dt(&gpio_spec)) {
		LOG_ERR("Device %s is not ready.", gpio_spec.port->name);
		atomic_inc(&completed_threads);
		return;
	}

	ret = gpio_pin_configure_dt(&gpio_spec, GPIO_OUTPUT);
	if (ret != 0) {
		LOG_ERR("gpio_pin_configure_dt(pin %d) returned %d", gpio_spec.pin, ret);
		atomic_inc(&completed_threads);
		return;
	}

	for (int i = 0; i < GPIO_THREAD_COUNT_MAX; i++) {
		ret = gpio_pin_toggle_dt(&gpio_spec);
		if (ret < 0) {
			LOG_ERR("gpio_pin_toggle_dt(pin %d) returned %d", gpio_spec.pin, ret);
			atomic_inc(&completed_threads);
			return;
		}

		LOG_INF("LED was toggled");
		k_msleep(GPIO_THREAD_SLEEP);
	}
	LOG_INF("GPIO thread has completed");

	atomic_inc(&completed_threads);
}

K_THREAD_DEFINE(thread_gpio_id, GPIO_THREAD_STACKSIZE, gpio_thread, NULL, NULL, NULL,
	K_PRIO_PREEMPT(GPIO_THREAD_PRIORITY), 0, 0);
```

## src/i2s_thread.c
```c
/*
 * Copyright (c) 2024 Nordic Semiconductor ASA
 *
 * SPDX-License-Identifier: LicenseRef-Nordic-5-Clause
 */

#include <zephyr/logging/log.h>
LOG_MODULE_REGISTER(i2s, LOG_LEVEL_INF);

#include <zephyr/drivers/i2s.h>
#include "common.h"

#if DT_NODE_HAS_STATUS(DT_ALIAS(i2s_node0), okay)

static const struct device *dev_i2s = DEVICE_DT_GET_OR_NULL(DT_ALIAS(i2s_node0));

#define SAMPLE_NO	32
#define FRAME_CLK_FREQ	8000
#define TIMEOUT		2000
#define NUM_RX_BLOCKS	4
#define NUM_TX_BLOCKS	4

/* The data_l represent a sine wave */
static int16_t data_l[SAMPLE_NO] = {
	  6392,  12539,  18204,  23169,  27244,  30272,  32137,  32767,  32137,
	 30272,  27244,  23169,  18204,  12539,   6392,      0,  -6393, -12540,
	-18205, -23170, -27245, -30273, -32138, -32767, -32138, -30273, -27245,
	-23170, -18205, -12540,  -6393,     -1,
};

/* The data_r represent a sine wave with double the frequency of data_l */
static int16_t data_r[SAMPLE_NO] = {
	 12539,  23169,  30272,  32767,  30272,  23169,  12539,      0, -12540,
	-23170, -30273, -32767, -30273, -23170, -12540,     -1,  12539,  23169,
	 30272,  32767,  30272,  23169,  12539,      0, -12540, -23170, -30273,
	-32767, -30273, -23170, -12540,     -1,
};

#define BLOCK_SIZE (2 * sizeof(data_l))

K_MEM_SLAB_DEFINE(rx_mem_slab, BLOCK_SIZE, NUM_RX_BLOCKS, 32);
K_MEM_SLAB_DEFINE(tx_mem_slab, BLOCK_SIZE, NUM_TX_BLOCKS, 32);


static void fill_buf(int16_t *tx_block, int att)
{
	for (int i = 0; i < SAMPLE_NO; i++) {
		tx_block[2 * i] = data_l[i] >> att;
		tx_block[2 * i + 1] = data_r[i] >> att;
	}
}

static int configure_stream(const struct device *dev_i2s, enum i2s_dir dir)
{
	int ret;
	struct i2s_config i2s_cfg;

	i2s_cfg.word_size = 16U;
	i2s_cfg.channels = 2U;
	i2s_cfg.format = I2S_FMT_DATA_FORMAT_I2S;
	i2s_cfg.frame_clk_freq = FRAME_CLK_FREQ;
	i2s_cfg.block_size = BLOCK_SIZE;
	i2s_cfg.timeout = TIMEOUT;

	if (dir == I2S_DIR_TX) {
		/* Configure the Transmit port as Master */
		i2s_cfg.options = I2S_OPT_FRAME_CLK_MASTER
				| I2S_OPT_BIT_CLK_MASTER;
	} else if (dir == I2S_DIR_RX) {
		/* Configure the Receive port as Slave */
		i2s_cfg.options = I2S_OPT_FRAME_CLK_SLAVE
				| I2S_OPT_BIT_CLK_SLAVE;
	} else { /* dir == I2S_DIR_BOTH */
		i2s_cfg.options = I2S_OPT_FRAME_CLK_MASTER
				| I2S_OPT_BIT_CLK_MASTER;
	}

	if (dir == I2S_DIR_TX || dir == I2S_DIR_BOTH) {
		i2s_cfg.mem_slab = &tx_mem_slab;
		ret = i2s_configure(dev_i2s, I2S_DIR_TX, &i2s_cfg);
		if (ret < 0) {
			LOG_ERR("Failed to configure I2S TX stream (%d)", ret);
			return -1;
		}
	}

	if (dir == I2S_DIR_RX || dir == I2S_DIR_BOTH) {
		i2s_cfg.mem_slab = &rx_mem_slab;
		ret = i2s_configure(dev_i2s, I2S_DIR_RX, &i2s_cfg);
		if (ret < 0) {
			LOG_ERR("Failed to configure I2S RX stream (%d)", ret);
			return -1;
		}
	}

	return 0;
}

static int tx_block_write(const struct device *dev_i2s, int att, int err)
{
	char tx_block[BLOCK_SIZE];
	int ret;

	fill_buf((uint16_t *)tx_block, att);
	ret = i2s_buf_write(dev_i2s, tx_block, BLOCK_SIZE);
	if (ret != err) {
		LOG_ERR("i2s_buf_write failed (%d)", ret);
		return ret;
	}

	return 0;
}

static int rx_block_read(const struct device *dev_i2s, int att)
{
	char rx_block[BLOCK_SIZE];	/* Data is received but left unalyzed */
	size_t rx_size;
	int ret;

	ret = i2s_buf_read(dev_i2s, rx_block, &rx_size);
	if (ret < 0 || rx_size != BLOCK_SIZE) {
		LOG_ERR("i2s_buf_read() failed (%d)", ret);
		return ret;
	}
	LOG_DBG("i2s_buf_read() received %d", rx_size);

	return 0;
}

/* I2S thread */
static void i2s_thread(void *arg1, void *arg2, void *arg3)
{
	ARG_UNUSED(arg1);
	ARG_UNUSED(arg2);
	ARG_UNUSED(arg3);

	int ret;

	atomic_inc(&started_threads);

	if (!device_is_ready(dev_i2s)) {
		LOG_ERR("Device %s is not ready.", dev_i2s->name);
		atomic_inc(&completed_threads);
		return;
	}

	/* Configure I2S */
	ret = configure_stream(dev_i2s, I2S_DIR_BOTH);
	if (ret < 0) {
		atomic_inc(&completed_threads);
		return;
	}

	for (int i = 0; i < I2S_THREAD_COUNT_MAX; i++) {
		/* Drop??? previous communication */
		ret = i2s_trigger(dev_i2s, I2S_DIR_BOTH, I2S_TRIGGER_DROP);
		if (ret < 0) {
			LOG_ERR("i2s_trigger(I2S_TRIGGER_DROP) TX/RX failed (%d)", ret);
			atomic_inc(&completed_threads);
			return;
		}

		/* Prefill TX queue */
		ret = tx_block_write(dev_i2s, 0, 0);
		if (ret != 0) {
			LOG_ERR("tx_block_write(0) failed (%d)", ret);
			atomic_inc(&completed_threads);
			return;
		}
		LOG_DBG("TX 1 - OK");

		ret = tx_block_write(dev_i2s, 1, 0);
		if (ret != 0) {
			LOG_ERR("tx_block_write(1) failed (%d)", ret);
			atomic_inc(&completed_threads);
			return;
		}
		LOG_DBG("TX 2 - OK");

		ret = i2s_trigger(dev_i2s, I2S_DIR_BOTH, I2S_TRIGGER_START);
		if (ret < 0) {
			LOG_ERR("i2s_trigger(I2S_TRIGGER_START) TX/RX failed (%d)", ret);
			atomic_inc(&completed_threads);
			return;
		}

		ret = rx_block_read(dev_i2s, 0);
		if (ret < 0) {
			LOG_ERR("rx_block_read(0) failed (%d)", ret);
			atomic_inc(&completed_threads);
			return;
		}
		LOG_DBG("RX 1 - OK");

		ret = tx_block_write(dev_i2s, 2, 0);
		if (ret != 0) {
			LOG_ERR("tx_block_write(2) failed (%d)", ret);
			atomic_inc(&completed_threads);
			return;
		}
		LOG_DBG("TX 3 - OK");

		/* All data written, drain TX queue and stop both streams. */
		ret = i2s_trigger(dev_i2s, I2S_DIR_BOTH, I2S_TRIGGER_DRAIN);
		if (ret < 0) {
			LOG_ERR("i2s_trigger(I2S_TRIGGER_DRAIN) TX/RX failed (%d)", ret);
			atomic_inc(&completed_threads);
			return;
		}

		ret = rx_block_read(dev_i2s, 1);
		if (ret < 0) {
			LOG_ERR("rx_block_read(1) failed (%d)", ret);
			atomic_inc(&completed_threads);
			return;
		}
		LOG_DBG("RX 2 - OK");

		ret = rx_block_read(dev_i2s, 2);
		if (ret < 0) {
			LOG_ERR("rx_block_read(2) failed (%d)", ret);
			atomic_inc(&completed_threads);
			return;
		}
		LOG_DBG("RX 3 - OK");

		LOG_INF("I2S data was sent");
		k_msleep(I2S_THREAD_SLEEP);
	}

	LOG_INF("I2S thread has completed");

	atomic_inc(&completed_threads);
}

K_THREAD_DEFINE(thread_i2s_id, I2S_THREAD_STACKSIZE, i2s_thread, NULL, NULL, NULL,
	K_PRIO_PREEMPT(I2S_THREAD_PRIORITY), 0, 0);

#else
#pragma message("I2S thread skipped due to missing node in the DTS")
#endif
```

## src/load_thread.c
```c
/*
 * Copyright (c) 2024 Nordic Semiconductor ASA
 *
 * SPDX-License-Identifier: LicenseRef-Nordic-5-Clause
 */

#include <zephyr/logging/log.h>
LOG_MODULE_REGISTER(load, LOG_LEVEL_INF);

#include "common.h"

static struct k_timer load_timer;
static atomic_t load_active;

void load_timer_handler(struct k_timer *dummy)
{
	atomic_set(&load_active, 0);
}

/* CPU load thread */
static void load_thread(void *arg1, void *arg2, void *arg3)
{
	ARG_UNUSED(arg1);
	ARG_UNUSED(arg2);
	ARG_UNUSED(arg3);

	atomic_inc(&started_threads);

	atomic_set(&load_active, 1);

	k_timer_init(&load_timer, load_timer_handler, NULL);

	/* start a one-shot timer that expires after LOAD_THREAD_DURATION */
	k_timer_start(&load_timer, K_MSEC(LOAD_THREAD_DURATION), K_FOREVER);

	while (atomic_get(&load_active) == 1) {
		k_busy_wait(1000);
		k_yield();
	}

	LOG_INF("CPU load thread has completed");

	atomic_inc(&completed_threads);
}

K_THREAD_DEFINE(thread_load_id, LOAD_THREAD_STACKSIZE, load_thread, NULL, NULL, NULL,
	K_PRIO_PREEMPT(LOAD_THREAD_PRIORITY), 0, 0);
```
